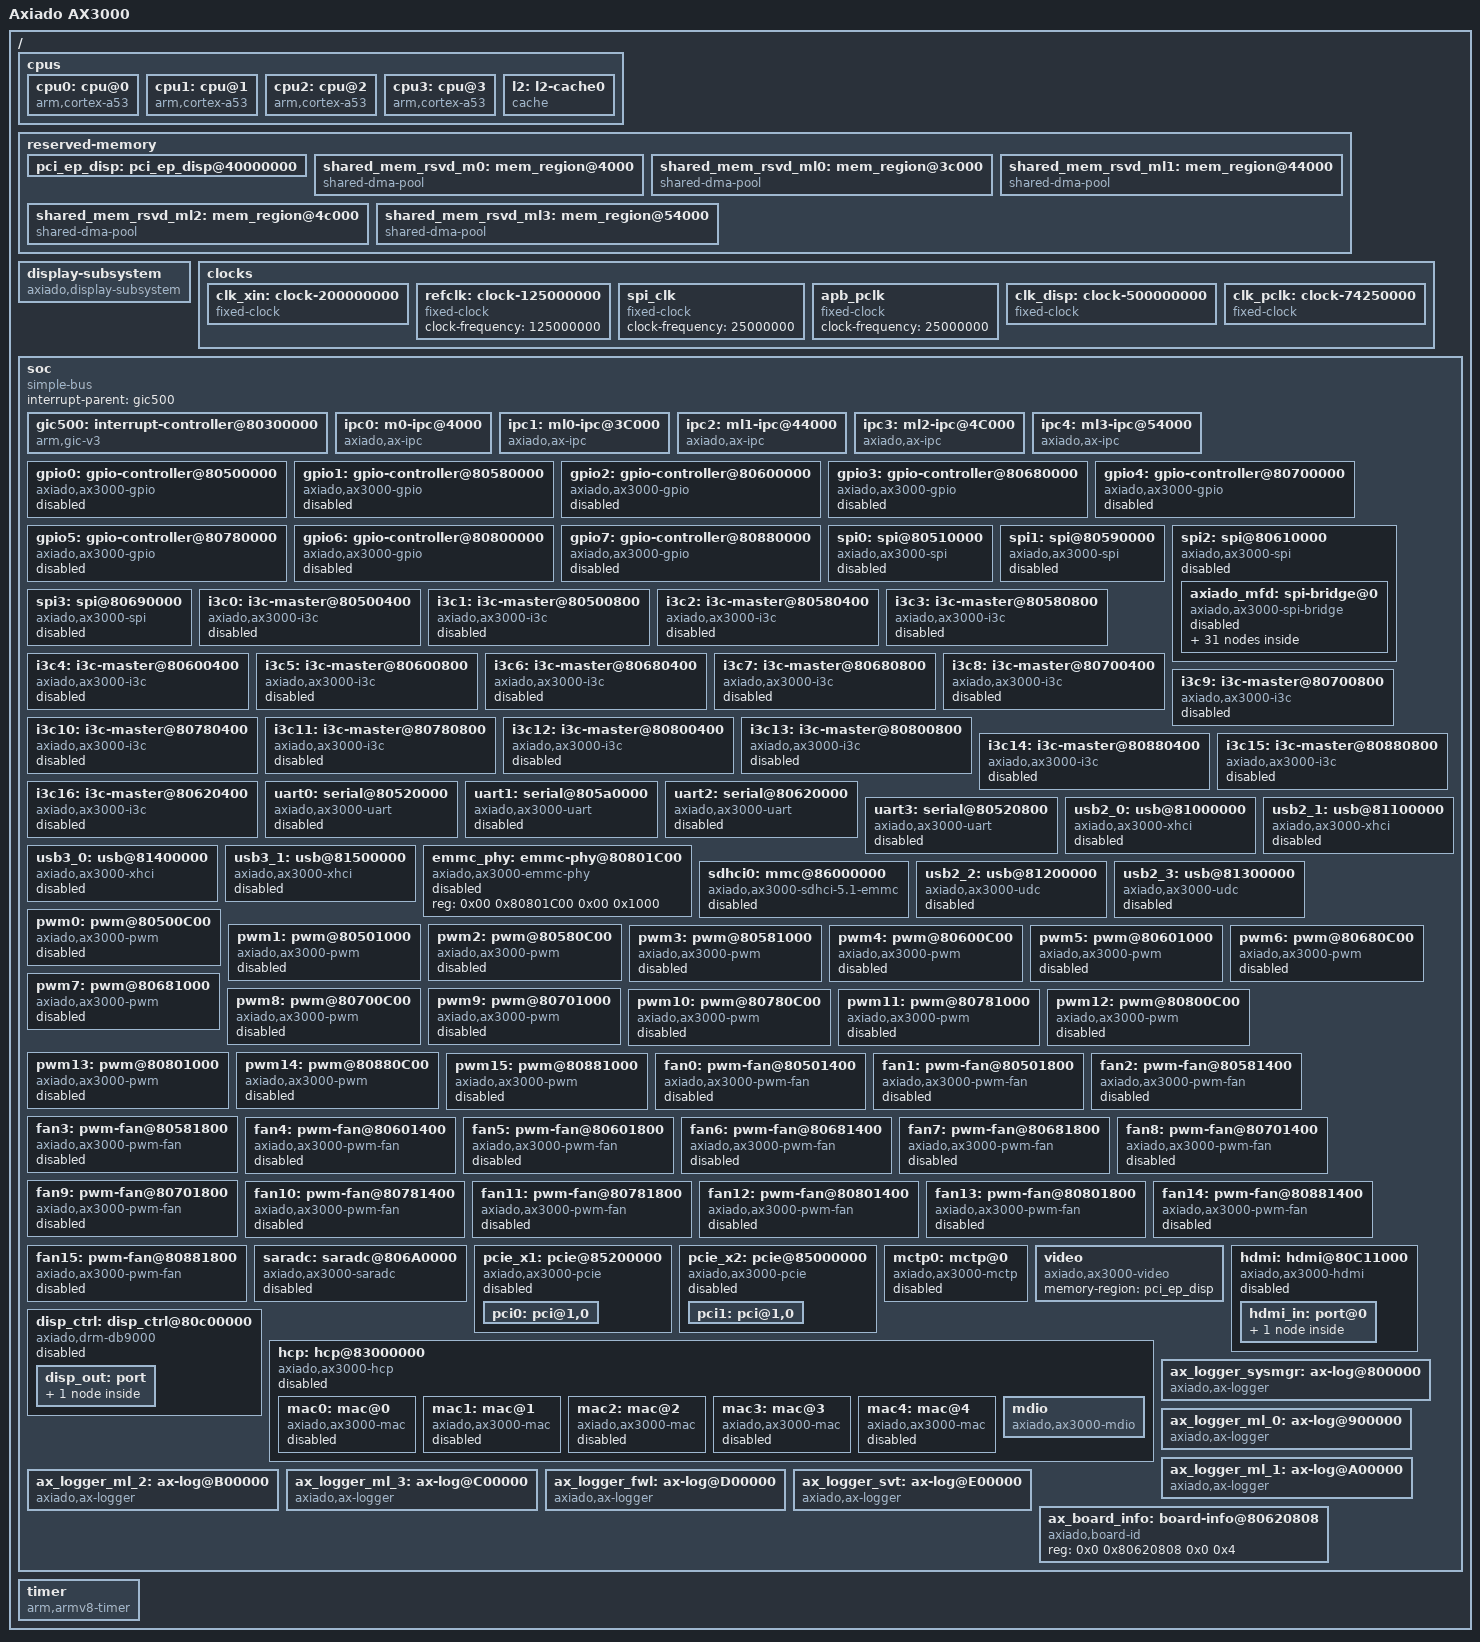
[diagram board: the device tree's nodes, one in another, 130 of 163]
// SPDX-License-Identifier: GPL-2.0+
/*
 * Copyright (c) 2021-25 Axiado Corporation (or its affiliates).
 */

/dts-v1/;

#include <dt-bindings/interrupt-controller/irq.h>
#include <dt-bindings/interrupt-controller/arm-gic.h>

/memreserve/ 0x3c0013a0 0x00000008;	/* cpu-release-addr */
/ {
	model = "Axiado AX3000";
	interrupt-parent = <&gic500>;
	#address-cells = <2>;
	#size-cells = <2>;

	cpus {
		#address-cells = <2>;
		#size-cells = <0>;

		cpu0: cpu@0 {
			device_type = "cpu";
			compatible = "arm,cortex-a53";
			reg = <0x0 0x0>;
			enable-method = "spin-table";
			cpu-release-addr = <0x0 0x3c0013a0>;
			d-cache-size = <0x8000>;
			d-cache-line-size = <64>;
			d-cache-sets = <128>;
			i-cache-size = <0x8000>;
			i-cache-line-size = <64>;
			i-cache-sets = <256>;
			next-level-cache = <&l2>;
		};

		cpu1: cpu@1 {
			device_type = "cpu";
			compatible = "arm,cortex-a53";
			reg = <0x0 0x1>;
			enable-method = "spin-table";
			cpu-release-addr = <0x0 0x3c0013a0>;
			d-cache-size = <0x8000>;
			d-cache-line-size = <64>;
			d-cache-sets = <128>;
			i-cache-size = <0x8000>;
			i-cache-line-size = <64>;
			i-cache-sets = <256>;
			next-level-cache = <&l2>;
		};

		cpu2: cpu@2 {
			device_type = "cpu";
			compatible = "arm,cortex-a53";
			reg = <0x0 0x2>;
			enable-method = "spin-table";
			cpu-release-addr = <0x0 0x3c0013a0>;
			d-cache-size = <0x8000>;
			d-cache-line-size = <64>;
			d-cache-sets = <128>;
			i-cache-size = <0x8000>;
			i-cache-line-size = <64>;
			i-cache-sets = <256>;
			next-level-cache = <&l2>;
		};

		cpu3: cpu@3 {
			device_type = "cpu";
			compatible = "arm,cortex-a53";
			reg = <0x0 0x3>;
			enable-method = "spin-table";
			cpu-release-addr = <0x0 0x3c0013a0>;
			d-cache-size = <0x8000>;
			d-cache-line-size = <64>;
			d-cache-sets = <128>;
			i-cache-size = <0x8000>;
			i-cache-line-size = <64>;
			i-cache-sets = <256>;
			next-level-cache = <&l2>;
		};

		l2: l2-cache0 {
			compatible = "cache";
			cache-size = <0x100000>;
			cache-unified;
			cache-line-size = <64>;
			cache-sets = <1024>;
			cache-level = <2>;
		};
	};

	reserved-memory {
		#address-cells = <2>;
		#size-cells = <2>;
		ranges;
		pci_ep_disp: pci_ep_disp@40000000 {
			reg = <0x00 0x40000000 0x00 0x8000000>,
			      <0x00 0x48000000 0x00 0x100000>;
			no-map;
		};
		shared_mem_rsvd_m0: mem_region@4000 {
			compatible = "shared-dma-pool";
			reg = <0x00 0x4000 0x00 0x8000>;
			no-map;
		};
		shared_mem_rsvd_ml0: mem_region@3c000 {
			compatible = "shared-dma-pool";
			reg = <0x00 0x3c000 0x00 0x8000>;
			no-map;
		};
		shared_mem_rsvd_ml1: mem_region@44000 {
			compatible = "shared-dma-pool";
			reg = <0x00 0x44000 0x00 0x8000>;
			no-map;
		};
		shared_mem_rsvd_ml2: mem_region@4c000 {
			compatible = "shared-dma-pool";
			reg = <0x00 0x4c000 0x00 0x8000>;
			no-map;
		};
		shared_mem_rsvd_ml3: mem_region@54000 {
			compatible = "shared-dma-pool";
			reg = <0x00 0x54000 0x00 0x8000>;
			no-map;
		};
	};

	display-subsystem {
		compatible = "axiado,display-subsystem";
	};

	clocks {
		clk_xin: clock-200000000 {
			compatible = "fixed-clock";
			#clock-cells = <0>;
			clock-frequency = <200000000>;
			clock-output-names = "clk_xin";
		};

		refclk: clock-125000000 {
			compatible = "fixed-clock";
			#clock-cells = <0>;
			clock-frequency = <125000000>;
		};

		spi_clk: spi_clk {
			compatible = "fixed-clock";
			#clock-cells = <0>;
			clock-frequency = <25000000>;
		};

		apb_pclk: apb_pclk {
			compatible = "fixed-clock";
			#clock-cells = <0>;
			clock-frequency = <25000000>;
		};

		clk_disp: clock-500000000 {
			compatible = "fixed-clock";
			#clock-cells = <0>;
			clock-frequency = <500000000>; /* 500MHz Clock half of CPU clock*/
			clock-output-names = "clk_disp";
		};

		clk_pclk: clock-74250000 {
			compatible = "fixed-clock";
			#clock-cells = <0>;
			clock-frequency = <74250000>;
			clock-output-names = "clk_pclk";
		};
	};

	soc {
		compatible = "simple-bus";
		ranges;
		#address-cells = <2>;
		#size-cells = <2>;
		interrupt-parent = <&gic500>;

		gic500: interrupt-controller@80300000 {
			compatible = "arm,gic-v3";
			reg = <0x00 0x80300000 0x00 0x10000>,
			      <0x00 0x80380000 0x00 0x80000>;
			ranges;
			#interrupt-cells = <3>;
			#address-cells = <2>;
			#size-cells = <2>;
			interrupt-controller;
			#redistributor-regions = <1>;
			interrupts = <GIC_PPI 9 IRQ_TYPE_LEVEL_HIGH>;
		};
		ipc0: m0-ipc@4000 {
			compatible = "axiado,ax-ipc";
			#interrupt-cells = <1>;
			reg = <0x00 0x4000 0x00 0x8000>,    /* Shared mem info */
			<0x0 0x88014120 0x0 0x4>,       /* TX intr mem info */
			<0x0 0x88014154 0x0 0x4>,       /* RX intr mem info */
			<0x0 0x02A00000 0x0 0x100000>,  /* Data buffers for A53->M0*/
			<0x0 0x80620804 0x0 0x4>,       /* scratchpad1 register, for boot status */
			<0x0 0x01500000 0x0 0x4>;       /* scratchpad region, for mmc partition */
			memory-region = <&shared_mem_rsvd_m0>;
			interrupts = <GIC_SPI 171 IRQ_TYPE_LEVEL_HIGH>;
			LABEL = "M0";
			interrupt-parent = <&gic500>;
			status = "okay";
		};
		ipc1: ml0-ipc@3C000 {
			compatible = "axiado,ax-ipc";
			#interrupt-cells = <1>;
			reg = <0x00 0x3C000 0x00 0x8000>,   /* Shared mem info */
			<0x0 0x88014140 0x0 0x4>,       /* TX intr mem info */
			<0x0 0x88000070 0x0 0x4>,       /* RX intr mem info */
			<0x0 0x04800000 0x0 0x100000>;  /* Data buffers for A53->ML0 */
			memory-region = <&shared_mem_rsvd_ml0>;
			interrupts = <GIC_SPI 195 IRQ_TYPE_LEVEL_HIGH>;
			LABEL = "ML0";
			interrupt-parent = <&gic500>;
			status = "okay";
		};
		ipc2: ml1-ipc@44000 {
			compatible = "axiado,ax-ipc";
			#interrupt-cells = <1>;
			reg = <0x00 0x44000 0x00 0x8000>,   /* Shared mem info */
			<0x0 0x88014144 0x0 0x4>,       /* TX intr mem info */
			<0x0 0x88002070 0x0 0x4>,       /* RX intr mem info */
			<0x0 0x11000000 0x0 0x100000>;  /* Data buffers for A53->ML1*/
			memory-region = <&shared_mem_rsvd_ml1>;
			interrupts = <GIC_SPI 196 IRQ_TYPE_LEVEL_HIGH>;
			LABEL = "ML1";
			interrupt-parent = <&gic500>;
			status = "okay";
		};
		ipc3: ml2-ipc@4C000 {
			compatible = "axiado,ax-ipc";
			#interrupt-cells = <1>;
			reg = <0x00 0x4C000 0x00 0x8000>,   /* Shared mem info */
			<0x0 0x88014148 0x0 0x4>,       /* TX intr mem info */
			<0x0 0x88004070 0x0 0x4>,       /* RX intr mem info */
			<0x0 0x1D800000 0x0 0x100000>;  /* Data buffers for A53->ML2*/
			memory-region = <&shared_mem_rsvd_ml2>;
			interrupts = <GIC_SPI 197 IRQ_TYPE_LEVEL_HIGH>;
			LABEL = "ML2";
			interrupt-parent = <&gic500>;
			status = "okay";
		};
		ipc4: ml3-ipc@54000 {
			compatible = "axiado,ax-ipc";
			#interrupt-cells = <1>;
			reg = <0x00 0x54000 0x00 0x8000>,   /* Shared mem info */
			<0x0 0x8801414c 0x0 0x4>,       /* TX intr mem info */
			<0x0 0x88006070 0x0 0x4>,       /* RX intr mem info */
			<0x0 0x2A000000 0x0 0x100000>;  /* Data buffers for A53->ML3*/
			memory-region = <&shared_mem_rsvd_ml3>;
			interrupts = <GIC_SPI 198 IRQ_TYPE_LEVEL_HIGH>;
			LABEL = "ML3";
			interrupt-parent = <&gic500>;
			status = "okay";
		};
		/* GPIO Controller banks 0 - 7 */
		gpio0: gpio-controller@80500000 {
			compatible = "axiado,ax3000-gpio", "cdns,gpio-r1p02";
			reg = <0x00 0x80500000 0x00 0x400>;
			clocks = <&refclk>;
			interrupt-parent = <&gic500>;
			interrupts = <GIC_SPI 183 IRQ_TYPE_LEVEL_HIGH>;
			gpio-controller;
			#gpio-cells = <2>;
			interrupt-controller;
			#interrupt-cells = <2>;
			status = "disabled";
		};

		gpio1: gpio-controller@80580000 {
			compatible = "axiado,ax3000-gpio", "cdns,gpio-r1p02";
			reg = <0x00 0x80580000 0x00 0x400>;
			clocks = <&refclk>;
			interrupt-parent = <&gic500>;
			interrupts = <GIC_SPI 184 IRQ_TYPE_LEVEL_HIGH>;
			gpio-controller;
			#gpio-cells = <2>;
			interrupt-controller;
			#interrupt-cells = <2>;
			status = "disabled";
		};

		gpio2: gpio-controller@80600000 {
			compatible = "axiado,ax3000-gpio", "cdns,gpio-r1p02";
			reg = <0x00 0x80600000 0x00 0x400>;
			clocks = <&refclk>;
			interrupt-parent = <&gic500>;
			interrupts = <GIC_SPI 185 IRQ_TYPE_LEVEL_HIGH>;
			gpio-controller;
			#gpio-cells = <2>;
			interrupt-controller;
			#interrupt-cells = <2>;
			status = "disabled";
		};

		gpio3: gpio-controller@80680000 {
			compatible = "axiado,ax3000-gpio", "cdns,gpio-r1p02";
			reg = <0x00 0x80680000 0x00 0x400>;
			clocks = <&refclk>;
			interrupt-parent = <&gic500>;
			interrupts = <GIC_SPI 186 IRQ_TYPE_LEVEL_HIGH>;
			gpio-controller;
			#gpio-cells = <2>;
			interrupt-controller;
			#interrupt-cells = <2>;
			status = "disabled";
		};

		gpio4: gpio-controller@80700000 {
			compatible = "axiado,ax3000-gpio", "cdns,gpio-r1p02";
			reg = <0x00 0x80700000 0x00 0x400>;
			clocks = <&refclk>;
			interrupt-parent = <&gic500>;
			interrupts = <GIC_SPI 187 IRQ_TYPE_LEVEL_HIGH>;
			gpio-controller;
			#gpio-cells = <2>;
			interrupt-controller;
			#interrupt-cells = <2>;
			status = "disabled";
		};

		gpio5: gpio-controller@80780000 {
			compatible = "axiado,ax3000-gpio", "cdns,gpio-r1p02";
			reg = <0x00 0x80780000 0x00 0x400>;
			clocks = <&refclk>;
			interrupt-parent = <&gic500>;
			interrupts = <GIC_SPI 188 IRQ_TYPE_LEVEL_HIGH>;
			gpio-controller;
			#gpio-cells = <2>;
			interrupt-controller;
			#interrupt-cells = <2>;
			status = "disabled";
		};

		gpio6: gpio-controller@80800000 {
			compatible = "axiado,ax3000-gpio", "cdns,gpio-r1p02";
			reg = <0x00 0x80800000 0x00 0x400>;
			clocks = <&refclk>;
			interrupt-parent = <&gic500>;
			interrupts = <GIC_SPI 189 IRQ_TYPE_LEVEL_HIGH>;
			gpio-controller;
			#gpio-cells = <2>;
			interrupt-controller;
			#interrupt-cells = <2>;
			status = "disabled";
		};

		gpio7: gpio-controller@80880000 {
			compatible = "axiado,ax3000-gpio", "cdns,gpio-r1p02";
			reg = <0x00 0x80880000 0x00 0x400>;
			clocks = <&refclk>;
			interrupt-parent = <&gic500>;
			interrupts = <GIC_SPI 190 IRQ_TYPE_LEVEL_HIGH>;
			gpio-controller;
			#gpio-cells = <2>;
			interrupt-controller;
			#interrupt-cells = <2>;
			status = "disabled";
		};

		spi0: spi@80510000 {
			compatible = "axiado,ax3000-spi";
			reg = <0x00 0x80510000 0x00 0x1000>;
			clock-names = "ref", "pclk";
			clocks = <&spi_clk>, <&apb_pclk>;
			interrupt-parent = <&gic500>;
			interrupts = <GIC_SPI 115 IRQ_TYPE_LEVEL_HIGH>;
			num-cs = <1>;
			status = "disabled";
		};

		spi1: spi@80590000 {
			compatible = "axiado,ax3000-spi";
			reg = <0x00 0x80590000 0x00 0x1000>;
			clock-names = "ref", "pclk";
			clocks = <&spi_clk>, <&apb_pclk>;
			interrupt-parent = <&gic500>;
			interrupts = <GIC_SPI 116 IRQ_TYPE_LEVEL_HIGH>;
			num-cs = <1>;
			status = "disabled";
		};

		spi2: spi@80610000 {
			compatible = "axiado,ax3000-spi";
			reg = <0x00 0x80610000 0x00 0x1000>;
			clock-names = "ref", "pclk";
			clocks = <&spi_clk>, <&apb_pclk>;
			interrupt-parent = <&gic500>;
			interrupts = <GIC_SPI 117 IRQ_TYPE_LEVEL_HIGH>;
			num-cs = <1>;
			#address-cells = <1>;
			#size-cells = <0>;
			status = "disabled";

			/* MFD parent device representing the Solang peripheral */
			axiado_mfd: spi-bridge@0 {
				compatible = "axiado,ax3000-spi-bridge", "axiado,spi-bridge";
				/* Current spi-axiado drv ignores the value from the device tree */
				spi-max-frequency = <25000000>;
				reg = <0x0>; /* Chip select 0 */
				#address-cells = <1>;
				#size-cells = <1>;
				interrupt-controller;
				#interrupt-cells = <1>;
				interrupt-names = "mfd-shared";
				interrupt-parent = <&gpio6>;
				/* GPIO_212 LTPI-I2C Interrupt */
				interrupts = <20 IRQ_TYPE_LEVEL_HIGH>;
				status = "disabled";
				mfd_i2c0: i2c-ssif@0 {
					compatible = "axiado,xps-iic-slave";
					#address-cells = <1>;
					#size-cells = <0>;
					reg = <0x0 0x800>;
					clocks = <&refclk &clk_xin>;
					#interrupt-cells = <2>;
					interrupt-parent = <&gpio6>;
					interrupts = <11 IRQ_TYPE_LEVEL_HIGH>; /* GPIO_203 I2C slave interrupt */
					clock-frequency = <100000>;
					/* Axiado-specific IRQ thread tuning */
					axiado,irq-rt-priority = <90>; /* 1..99, SCHED_FIFO */
					axiado,irq-cpu = <2>; /* pin threaded IRQ to CPU2 */
					status = "disabled";
					ssif-bmc@10 {
						compatible = "ssif-bmc";
						reg = <0x10>;
						status = "disabled";
					};
				};
				mfd_i2c0_cdns: i2c@0 {
					compatible = "axiado,ax3000-i2c";
					#address-cells = <1>;
					#size-cells = <0>;
					reg = <0x0 0x800>;
					clocks = <&refclk &clk_xin>;
					#interrupt-cells = <2>;
					interrupt-parent = <&gpio6>;
					/* GPIO_203 I2C slave interrupt */
					interrupts = <11 IRQ_TYPE_LEVEL_HIGH>;
					clock-frequency = <100000>;
					status = "disabled";
				};
				/* Child node for the second Cadence I2C IP */
				mfd_i2c1: i2c@800 {
					compatible = "axiado,ax3000-i2c";
					reg = <0x0800 0x400>; /* i2c_1_base_addr and size */
					#interrupt-cells = <2>;
					interrupt-parent = <&gpio6>;
					/* Direct GPIO 204 IRQ */
					interrupts = <12 IRQ_TYPE_LEVEL_HIGH>;
					clocks = <&refclk &clk_xin>;
					clock-frequency = <100000>;
					status = "disabled";
				};
				mfd_i2c2: i2c@c00 {
					compatible = "axiado,ax3000-i2c";
					reg = <0x0c00 0x400>; /* i2c_2_base_addr and size */
					#interrupt-cells = <2>;
					interrupt-parent = <&gpio6>;
					/* Direct GPIO 205 IRQ */
					interrupts = <13 IRQ_TYPE_LEVEL_HIGH>;
					clocks = <&refclk &clk_xin>;
					clock-frequency = <100000>;
					status = "disabled";
				};
				mfd_i2c3: i2c@1000 {
					compatible = "axiado,ax3000-i2c";
					reg = <0x1000 0x400>; /* i2c_3_base_addr and size */
					#interrupt-cells = <2>;
					interrupt-parent = <&gpio6>;
					/* Direct GPIO 206 IRQ */
					interrupts = <14 IRQ_TYPE_LEVEL_HIGH>;
					clocks = <&refclk &clk_xin>;
					clock-frequency = <100000>;
					status = "disabled";
				};
				mfd_i2c4: i2c@1400 {
					compatible = "axiado,ax3000-i2c";
					reg = <0x1400 0x400>; /* i2c_4_base_addr and size */
					#interrupt-cells = <2>;
					interrupt-parent = <&gpio6>;
					/* Direct GPIO 207 IRQ */
					interrupts = <15 IRQ_TYPE_LEVEL_HIGH>;
					clocks = <&refclk &clk_xin>;
					clock-frequency = <100000>;
					status = "disabled";
				};
				mfd_i2c5: i2c@1800 {
					compatible = "axiado,ax3000-i2c";
					reg = <0x1800 0x400>; /* i2c_5_base_addr and size */
					#interrupt-cells = <2>;
					interrupt-parent = <&gpio6>;
					/* Direct GPIO 208 IRQ */
					interrupts = <16 IRQ_TYPE_LEVEL_HIGH>;
					clocks = <&refclk &clk_xin>;
					clock-frequency = <100000>;
					status = "disabled";
				};
				mfd_i2c6: i2c@1c00 {
					compatible = "axiado,ax3000-i2c";
					reg = <0x1c00 0x400>; /* i2c_6_base_addr and size */
					#interrupt-cells = <2>;
					interrupt-parent = <&gpio6>;
					/* Direct GPIO 217 IRQ */
					interrupts = <25 IRQ_TYPE_LEVEL_HIGH>;
					clocks = <&refclk &clk_xin>;
					clock-frequency = <100000>;
					status = "disabled";
				};
				mfd_i2c7: i2c@2000 {
					compatible = "axiado,ax3000-i2c";
					reg = <0x2000 0x400>; /* i2c_7_base_addr and size */
					#interrupt-cells = <2>;
					interrupt-parent = <&gpio6>;
					/* Direct GPIO 219 IRQ */
					interrupts = <27 IRQ_TYPE_LEVEL_HIGH>;
					clocks = <&refclk &clk_xin>;
					clock-frequency = <100000>;
					status = "disabled";
				};
				mfd_i2c8: i2c@2400 {
					compatible = "axiado,ax3000-i2c";
					reg = <0x2400 0x400>; /* i2c_8_base_addr and size */
					#interrupt-cells = <2>;
					interrupt-parent = <&gpio6>;
					/* Direct GPIO 220 IRQ */
					interrupts = <28 IRQ_TYPE_LEVEL_HIGH>;
					clocks = <&refclk &clk_xin>;
					clock-frequency = <100000>;
					status = "disabled";
				};
				mfd_i2c9: i2c@2800 {
					compatible = "axiado,ax3000-i2c";
					reg = <0x2800 0x400>; /* i2c_9_base_addr and size */
					#interrupt-cells = <2>;
					interrupt-parent = <&gpio6>;
					/* Direct GPIO 221 IRQ */
					interrupts = <29 IRQ_TYPE_LEVEL_HIGH>;
					clocks = <&refclk &clk_xin>;
					clock-frequency = <100000>;
					status = "disabled";
				};
				mfd_i2c10: i2c@2c00 {
					compatible = "axiado,ax3000-i2c";
					reg = <0x2c00 0x400>; /* i2c_10_base_addr and size */
					#interrupt-cells = <2>;
					interrupt-parent = <&gpio6>;
					/* Direct GPIO 222 IRQ */
					interrupts = <30 IRQ_TYPE_LEVEL_HIGH>;
					clocks = <&refclk &clk_xin>;
					clock-frequency = <100000>;
					status = "disabled";
				};
				mfd_i2c11: i2c@3000 {
					compatible = "axiado,ax3000-i2c";
					reg = <0x3000 0x400>; /* i2c_11_base_addr and size */
					#interrupt-cells = <2>;
					interrupt-parent = <&gpio7>;
					/* Direct GPIO 245 IRQ */
					interrupts = <21 IRQ_TYPE_LEVEL_HIGH>;
					clocks = <&refclk &clk_xin>;
					clock-frequency = <100000>;
					status = "disabled";
				};
				mfd_i2c12: i2c@3400 {
					compatible = "axiado,ax3000-i2c";
					reg = <0x3400 0x400>; /* i2c_12_base_addr and size */
					#interrupt-cells = <2>;
					interrupt-parent = <&gpio7>;
					/* Direct GPIO 237 IRQ */
					interrupts = <13 IRQ_TYPE_LEVEL_HIGH>;
					clocks = <&refclk &clk_xin>;
					clock-frequency = <100000>;
					status = "disabled";
				};
				mfd_i2c13: i2c@3800 {
					compatible = "axiado,ax3000-i2c";
					reg = <0x3800 0x400>; /* i2c_13_base_addr and size */
					#interrupt-cells = <2>;
					interrupt-parent = <&gpio7>;
					/* Direct GPIO 238 IRQ */
					interrupts = <14 IRQ_TYPE_LEVEL_HIGH>;
					clocks = <&refclk &clk_xin>;
					clock-frequency = <100000>;
					status = "disabled";
				};
				mfd_i2c14: i2c@3c00 {
					compatible = "axiado,ax3000-i2c";
					reg = <0x3c00 0x400>; /* i2c_14_base_addr and size */
					#interrupt-cells = <2>;
					interrupt-parent = <&gpio7>;
					/* Direct GPIO 239 IRQ */
					interrupts = <15 IRQ_TYPE_LEVEL_HIGH>;
					clocks = <&refclk &clk_xin>;
					clock-frequency = <100000>;
					status = "disabled";
				};
				mfd_i2c15: i2c@4000 {
					compatible = "axiado,ax3000-i2c";
					reg = <0x4000 0x400>; /* i2c_15_base_addr and size */
					#interrupt-cells = <2>;
					interrupt-parent = <&gpio7>;
					/* Direct GPIO 240 IRQ */
					interrupts = <16 IRQ_TYPE_LEVEL_HIGH>;
					clocks = <&refclk &clk_xin>;
					clock-frequency = <100000>;
					status = "disabled";
				};
				mfd_i2c16: i2c@4400 {
					compatible = "axiado,ax3000-i2c";
					reg = <0x4400 0x400>; /* i2c_16_base_addr and size */
					#interrupt-cells = <2>;
					interrupt-parent = <&gpio7>;
					/* Direct GPIO 241 IRQ */
					interrupts = <17 IRQ_TYPE_LEVEL_HIGH>;
					clocks = <&refclk &clk_xin>;
					clock-frequency = <100000>;
					status = "disabled";
				};
				ltpi_i2c17: i2c@4800 {
					compatible = "axiado,ax3000-i2c";
					reg = <0x4800 0x400>; /* i2c_14_base_addr and size */
					interrupt-parent = <&axiado_mfd>;
					#interrupt-cells = <1>;
					interrupts = <17>;
					clocks = <&refclk &clk_xin>;
					clock-frequency = <100000>;
					status = "disabled";
				};
				ltpi_i2c18: i2c@4c00 {
					compatible = "axiado,ax3000-i2c";
					reg = <0x4c00 0x400>; /* i2c_18_base_addr and size */
					interrupt-controller;
					#interrupt-cells = <1>;
					interrupts = <18>;
					clocks = <&refclk &clk_xin>;
					clock-frequency = <100000>;
					status = "disabled";
				};
				ltpi_i2c19: i2c@5000 {
					compatible = "axiado,ax3000-i2c";
					reg = <0x5000 0x400>; /* i2c_19_base_addr and size */
					interrupt-controller;
					#interrupt-cells = <1>;
					interrupts = <19>;
					clocks = <&refclk &clk_xin>;
					clock-frequency = <100000>;
					status = "disabled";
				};
				ltpi_i2c20: i2c@5400 {
					compatible = "axiado,ax3000-i2c";
					reg = <0x5400 0x400>; /* i2c_20 and size */
					interrupt-controller;
					#interrupt-cells = <1>;
					interrupts = <20>;
					clocks = <&refclk &clk_xin>;
					clock-frequency = <100000>;
					status = "disabled";
				};
				ltpi_i2c21: i2c@5800 {
					compatible = "axiado,ax3000-i2c";
					reg = <0x5800 0x400>; /* i2c_21 and size */
					interrupt-controller;
					#interrupt-cells = <1>;
					interrupts = <21>;
					clocks = <&refclk &clk_xin>;
					clock-frequency = <100000>;
					status = "disabled";
				};
				ltpi_i2c22: i2c@5c00 {
					compatible = "axiado,ax3000-i2c";
					reg = <0x5c00 0x400>; /* i2c_22 and size */
					interrupt-controller;
					#interrupt-cells = <1>;
					interrupts = <22>;
					clocks = <&refclk &clk_xin>;
					clock-frequency = <100000>;
					status = "disabled";
				};
				mfd_sgpio0: sgpio@a000 {
					compatible = "axiado,sgpio";
					reg = <0xa000 0x800>;
					gpio-controller;
					#gpio-cells = <2>;
					interrupt-parent = <&gpio6>;
					/* GPIO_209 SGPIO Interrupt */
					interrupts = <17 IRQ_TYPE_LEVEL_HIGH>;
					/* Design variants 128 bit or 512 bit */
					design-variant = <128>;
					/* Supports maximum of 128 pins */
					ngpios = <128>;
					/* SGPIO Clock frequency 12 MHz */
					bus-frequency = <12000000>;
					apb-frequency = <100000000>;
					dout-init = <0x00000000 0x00000000 0x00000000 0x00000000>;
					status = "disabled";
				};
				mfd_ltpi0: ltpi@8000 {
					compatible = "axiado,ltpi";
					/* Base offset for regmap */
					reg = <0x8000 0x2000>;
					gpio-controller;
					#gpio-cells = <2>;
					interrupt-parent = <&gpio6>;
					/* GPIO_210 SGPIO Interrupt */
					interrupts = <18 IRQ_TYPE_LEVEL_HIGH>;
					interrupt-controller;
					#interrupt-cells = <2>;
					/* Supports maximum of 128 pins */
					ngpios = <128>;
					dout-init = <0x00000000 0x00000000 0x00000000 0x00000000>;
					status = "disabled";
				};
				mfd_espi: espi@c000 {
					compatible = "axiado,ax3000-espi-regmap";
					reg = <0xc000 0x1000>,
						<0xd000 0x1000>,
						<0xe000 0x1000>;
					reg-names = "espi-core", "espi-perif", "espi-atu";
					interrupt-parent = <&gpio6>;
					interrupts = <19 IRQ_TYPE_LEVEL_HIGH>,   /* GPIO_211 eSPI core */
						   <23 IRQ_TYPE_LEVEL_HIGH>;   /* GPIO_215 external logic */
					interrupt-names = "espi-core-intr", "ext-logic-intr";
					interrupt-controller;
					#interrupt-cells = <1>;
					#address-cells = <1>;
					#size-cells = <1>;
					status = "disabled";

					espi_kcs0: espi-kcs@0 {
						compatible = "axiado,ax3000-kcs-bmc";
						reg = <0x0 0x10>;
						interrupts = <0>; /* Virtual IRQ: bit 0 in external logic ISR */
						interrupt-parent = <&mfd_espi>;
						channel-index = <0>;
						io-addr = <0xCA2>; /* IPMI 2.0: 0xCA2(data) + 0xCA3 (status) */
						host-status-offset = <0x1>; /* 1-byte offset per IPMI 2.0 spec */
						status = "disabled";
					};

					espi_snoop: espi-snoop@C0 {
						compatible = "axiado,ax3000-espi-snoop";
						reg = <0xC0 0x10>;
						interrupts = <13>;
						interrupt-parent = <&mfd_espi>;
						io-addr = <0x80>;
						status = "disabled";
					};

					espi_uart0: espi-uart@40 {
						compatible = "axiado,ax3000-espi-uart";
						reg = <0x40 0x02>;
						interrupts = <5>; /* Virtual IRQ: bit 5 */
						interrupt-parent = <&mfd_espi>;
						clock-names = "uart_clk", "pclk";
						clocks = <&refclk &refclk>;
						channel-index = <0>;
						io-addr = <0x3F8>;
						fifo-size = <16>;
						cpu-fifo-size = <64>;
						status = "disabled";
					};
				};
			};
		};

		spi3: spi@80690000 {
			compatible = "axiado,ax3000-spi";
			reg = <0x00 0x80690000 0x00 0x1000>;
			clock-names = "ref", "pclk";
			clocks = <&spi_clk>, <&apb_pclk>;
			interrupt-parent = <&gic500>;
			interrupts = <GIC_SPI 118 IRQ_TYPE_LEVEL_HIGH>;
			num-cs = <1>;
			status = "disabled";
		};

		/* I3C Controller 0 - 16 */
		i3c0: i3c-master@80500400 {
			compatible = "axiado,ax3000-i3c", "cdns,i3c-master";
			reg = <0x00 0x80500400 0x00 0x400>;
			clocks = <&refclk &clk_xin>;
			clock-names = "pclk", "sysclk";
			interrupt-parent = <&gic500>;
			interrupts = <GIC_SPI 76 IRQ_TYPE_LEVEL_HIGH>;
			i2c-scl-hz = <100000>;
			i3c-scl-hz = <400000>;
			#address-cells = <3>;
			#size-cells = <0>;
			status = "disabled";
			disable-ibir;
			use-i2c-alias;
		};

		i3c1: i3c-master@80500800 {
			compatible = "axiado,ax3000-i3c", "cdns,i3c-master";
			reg = <0x00 0x80500800 0x00 0x400>;
			clocks = <&refclk &clk_xin>;
			clock-names = "pclk", "sysclk";
			interrupt-parent = <&gic500>;
			interrupts = <GIC_SPI 77 IRQ_TYPE_LEVEL_HIGH>;
			i2c-scl-hz = <100000>;
			i3c-scl-hz = <400000>;
			#address-cells = <3>;
			#size-cells = <0>;
			status = "disabled";
			disable-ibir;
			use-i2c-alias;
		};

		i3c2: i3c-master@80580400 {
			compatible = "axiado,ax3000-i3c", "cdns,i3c-master";
			reg = <0x00 0x80580400 0x00 0x400>;
			clocks = <&refclk &clk_xin>;
			clock-names = "pclk", "sysclk";
			interrupt-parent = <&gic500>;
			interrupts = <GIC_SPI 78 IRQ_TYPE_LEVEL_HIGH>;
			i2c-scl-hz = <100000>;
			i3c-scl-hz = <400000>;
			#address-cells = <3>;
			#size-cells = <0>;
			status = "disabled";
			disable-ibir;
			use-i2c-alias;
		};

		i3c3: i3c-master@80580800 {
			compatible = "axiado,ax3000-i3c", "cdns,i3c-master";
			reg = <0x00 0x80580800 0x00 0x400>;
			clocks = <&refclk &clk_xin>;
			clock-names = "pclk", "sysclk";
			interrupt-parent = <&gic500>;
			interrupts = <GIC_SPI 79 IRQ_TYPE_LEVEL_HIGH>;
			i2c-scl-hz = <100000>;
			i3c-scl-hz = <400000>;
			#address-cells = <3>;
			#size-cells = <0>;
			status = "disabled";
			disable-ibir;
			use-i2c-alias;
		};

		i3c4: i3c-master@80600400 {
			compatible = "axiado,ax3000-i3c", "cdns,i3c-master";
			reg = <0x00 0x80600400 0x00 0x400>;
			clocks = <&refclk &clk_xin>;
			clock-names = "pclk", "sysclk";
			interrupt-parent = <&gic500>;
			interrupts = <GIC_SPI 80 IRQ_TYPE_LEVEL_HIGH>;
			i2c-scl-hz = <100000>;
			i3c-scl-hz = <400000>;
			#address-cells = <3>;
			#size-cells = <0>;
			status = "disabled";
			disable-ibir;
			use-i2c-alias;
		};

		i3c5: i3c-master@80600800 {
			compatible = "axiado,ax3000-i3c", "cdns,i3c-master";
			reg = <0x00 0x80600800 0x00 0x400>;
			clocks = <&refclk &clk_xin>;
			clock-names = "pclk", "sysclk";
			interrupt-parent = <&gic500>;
			interrupts = <GIC_SPI 81 IRQ_TYPE_LEVEL_HIGH>;
			i2c-scl-hz = <100000>;
			i3c-scl-hz = <400000>;
			#address-cells = <3>;
			#size-cells = <0>;
			status = "disabled";
			disable-ibir;
			use-i2c-alias;
		};

		i3c6: i3c-master@80680400 {
			compatible = "axiado,ax3000-i3c", "cdns,i3c-master";
			reg = <0x00 0x80680400 0x00 0x400>;
			clocks = <&refclk &clk_xin>;
			clock-names = "pclk", "sysclk";
			interrupt-parent = <&gic500>;
			interrupts = <GIC_SPI 82 IRQ_TYPE_LEVEL_HIGH>;
			i2c-scl-hz = <100000>;
			i3c-scl-hz = <400000>;
			#address-cells = <3>;
			#size-cells = <0>;
			status = "disabled";
			disable-ibir;
			use-i2c-alias;
		};

		i3c7: i3c-master@80680800 {
			compatible = "axiado,ax3000-i3c", "cdns,i3c-master";
			reg = <0x00 0x80680800 0x00 0x400>;
			clocks = <&refclk &clk_xin>;
			clock-names = "pclk", "sysclk";
			interrupt-parent = <&gic500>;
			interrupts = <GIC_SPI 83 IRQ_TYPE_LEVEL_HIGH>;
			i2c-scl-hz = <100000>;
			i3c-scl-hz = <400000>;
			#address-cells = <3>;
			#size-cells = <0>;
			status = "disabled";
			disable-ibir;
			use-i2c-alias;
		};

		i3c8: i3c-master@80700400 {
			compatible = "axiado,ax3000-i3c", "cdns,i3c-master";
			reg = <0x00 0x80700400 0x00 0x400>;
			clocks = <&refclk &clk_xin>;
			clock-names = "pclk", "sysclk";
			interrupt-parent = <&gic500>;
			interrupts = <GIC_SPI 84 IRQ_TYPE_LEVEL_HIGH>;
			i2c-scl-hz = <100000>;
			i3c-scl-hz = <400000>;
			#address-cells = <3>;
			#size-cells = <0>;
			status = "disabled";
			disable-ibir;
			use-i2c-alias;
		};

		i3c9: i3c-master@80700800 {
			compatible = "axiado,ax3000-i3c", "cdns,i3c-master";
			reg = <0x00 0x80700800 0x00 0x400>;
			clocks = <&refclk &clk_xin>;
			clock-names = "pclk", "sysclk";
			interrupt-parent = <&gic500>;
			interrupts = <GIC_SPI 85 IRQ_TYPE_LEVEL_HIGH>;
			i2c-scl-hz = <100000>;
			i3c-scl-hz = <400000>;
			#address-cells = <3>;
			#size-cells = <0>;
			status = "disabled";
			disable-ibir;
			use-i2c-alias;
		};

		i3c10: i3c-master@80780400 {
			compatible = "axiado,ax3000-i3c", "cdns,i3c-master";
			reg = <0x00 0x80780400 0x00 0x400>;
			clocks = <&refclk &clk_xin>;
			clock-names = "pclk", "sysclk";
			interrupt-parent = <&gic500>;
			interrupts = <GIC_SPI 86 IRQ_TYPE_LEVEL_HIGH>;
			i2c-scl-hz = <100000>;
			i3c-scl-hz = <400000>;
			#address-cells = <3>;
			#size-cells = <0>;
			status = "disabled";
			disable-ibir;
			use-i2c-alias;
		};

		i3c11: i3c-master@80780800 {
			compatible = "axiado,ax3000-i3c", "cdns,i3c-master";
			reg = <0x00 0x80780800 0x00 0x400>;
			clocks = <&refclk &clk_xin>;
			clock-names = "pclk", "sysclk";
			interrupt-parent = <&gic500>;
			interrupts = <GIC_SPI 87 IRQ_TYPE_LEVEL_HIGH>;
			i2c-scl-hz = <100000>;
			i3c-scl-hz = <400000>;
			#address-cells = <3>;
			#size-cells = <0>;
			status = "disabled";
			disable-ibir;
			use-i2c-alias;
		};

		i3c12: i3c-master@80800400 {
			compatible = "axiado,ax3000-i3c", "cdns,i3c-master";
			reg = <0x00 0x80800400 0x00 0x400>;
			clocks = <&refclk &clk_xin>;
			clock-names = "pclk", "sysclk";
			interrupt-parent = <&gic500>;
			interrupts = <GIC_SPI 88 IRQ_TYPE_LEVEL_HIGH>;
			i2c-scl-hz = <100000>;
			i3c-scl-hz = <400000>;
			#address-cells = <3>;
			#size-cells = <0>;
			status = "disabled";
			disable-ibir;
			use-i2c-alias;
		};

		i3c13: i3c-master@80800800 {
			compatible = "axiado,ax3000-i3c", "cdns,i3c-master";
			reg = <0x00 0x80800800 0x00 0x400>;
			clocks = <&refclk &clk_xin>;
			clock-names = "pclk", "sysclk";
			interrupt-parent = <&gic500>;
			interrupts = <GIC_SPI 89 IRQ_TYPE_LEVEL_HIGH>;
			i2c-scl-hz = <100000>;
			i3c-scl-hz = <400000>;
			#address-cells = <3>;
			#size-cells = <0>;
			status = "disabled";
			disable-ibir;
			use-i2c-alias;
		};

		i3c14: i3c-master@80880400 {
			compatible = "axiado,ax3000-i3c", "cdns,i3c-master";
			reg = <0x00 0x80880400 0x00 0x400>;
			clocks = <&refclk &clk_xin>;
			clock-names = "pclk", "sysclk";
			interrupt-parent = <&gic500>;
			interrupts = <GIC_SPI 90 IRQ_TYPE_LEVEL_HIGH>;
			i2c-scl-hz = <100000>;
			i3c-scl-hz = <400000>;
			#address-cells = <3>;
			#size-cells = <0>;
			status = "disabled";
			disable-ibir;
			use-i2c-alias;
		};

		i3c15: i3c-master@80880800 {
			compatible = "axiado,ax3000-i3c", "cdns,i3c-master";
			reg = <0x00 0x80880800 0x00 0x400>;
			clocks = <&refclk &clk_xin>;
			clock-names = "pclk", "sysclk";
			interrupt-parent = <&gic500>;
			interrupts = <GIC_SPI 91 IRQ_TYPE_LEVEL_HIGH>;
			i2c-scl-hz = <100000>;
			i3c-scl-hz = <400000>;
			#address-cells = <3>;
			#size-cells = <0>;
			status = "disabled";
			disable-ibir;
			use-i2c-alias;
		};

		i3c16: i3c-master@80620400 {
			compatible = "axiado,ax3000-i3c", "cdns,i3c-master";
			reg = <0x00 0x80620400 0x00 0x400>;
			clocks = <&refclk &clk_xin>;
			clock-names = "pclk", "sysclk";
			interrupt-parent = <&gic500>;
			interrupts = <GIC_SPI 92 IRQ_TYPE_LEVEL_HIGH>;
			i2c-scl-hz = <100000>;
			i3c-scl-hz = <400000>;
			#address-cells = <3>;
			#size-cells = <0>;
			status = "disabled";
			disable-ibir;
			use-i2c-alias;
		};

		uart0: serial@80520000 {
			compatible = "axiado,ax3000-uart", "cdns,uart-r1p12";
			reg = <0x00 0x80520000 0x00 0x100>;
			interrupt-parent = <&gic500>;
			interrupts = <GIC_SPI 112 IRQ_TYPE_LEVEL_HIGH>;
			clock-names = "uart_clk", "pclk";
			clocks = <&refclk &refclk>;
			status = "disabled";
		};

		uart1: serial@805a0000 {
			compatible = "axiado,ax3000-uart", "cdns,uart-r1p12";
			reg = <0x00 0x805A0000 0x00 0x100>;
			interrupt-parent = <&gic500>;
			interrupts = <GIC_SPI 113 IRQ_TYPE_LEVEL_HIGH>;
			clock-names = "uart_clk", "pclk";
			clocks = <&refclk &refclk>;
			status = "disabled";
		};

		uart2: serial@80620000 {
			compatible = "axiado,ax3000-uart", "cdns,uart-r1p12";
			reg = <0x00 0x80620000 0x00 0x100>;
			interrupt-parent = <&gic500>;
			interrupts = <GIC_SPI 114 IRQ_TYPE_LEVEL_HIGH>;
			clock-names = "uart_clk", "pclk";
			clocks = <&refclk &refclk>;
			status = "disabled";
		};

		uart3: serial@80520800 {
			compatible = "axiado,ax3000-uart", "cdns,uart-r1p12";
			reg = <0x00 0x80520800 0x00 0x100>;
			interrupt-parent = <&gic500>;
			interrupts = <GIC_SPI 170 IRQ_TYPE_LEVEL_HIGH>;
			clock-names = "uart_clk", "pclk";
			clocks = <&refclk &refclk>;
			status = "disabled";
		};

		usb2_0: usb@81000000 {
			compatible = "axiado,ax3000-xhci", "generic-xhci";
			reg = <0x00 0x81000000 0x00 0x100000>;
			interrupt-parent = <&gic500>;
			interrupts = <GIC_SPI 19 IRQ_TYPE_LEVEL_HIGH>;
			status = "disabled";
		};

		usb2_1: usb@81100000 {
			compatible = "axiado,ax3000-xhci", "generic-xhci";
			reg = <0x00 0x81100000 0x00 0x100000>;
			interrupt-parent = <&gic500>;
			interrupts = <GIC_SPI 20 IRQ_TYPE_LEVEL_HIGH>;
			status = "disabled";
		};

		usb3_0: usb@81400000 {
			compatible = "axiado,ax3000-xhci", "generic-xhci";
			reg = <0x00 0x81400000 0x00 0x100000>;
			interrupt-parent = <&gic500>;
			interrupts = <GIC_SPI 17 IRQ_TYPE_LEVEL_HIGH>;
			status = "disabled";
		};

		usb3_1: usb@81500000 {
			compatible = "axiado,ax3000-xhci", "generic-xhci";
			reg = <0x00 0x81500000 0x00 0x100000>;
			interrupt-parent = <&gic500>;
			interrupts = <GIC_SPI 18 IRQ_TYPE_LEVEL_HIGH>;
			status = "disabled";
		};

		emmc_phy: emmc-phy@80801C00 {
			compatible = "axiado,ax3000-emmc-phy";
			reg = <0x00 0x80801C00 0x00 0x1000>;
			#phy-cells = <0>;
			status = "disabled";
		};

		sdhci0: mmc@86000000 {
			compatible = "axiado,ax3000-sdhci-5.1-emmc", "arasan,sdhci-5.1";
			reg = <0x0 0x86000000 0x00 0x1000>;
			clock-names = "clk_xin", "clk_ahb";
			clocks = <&clk_xin &clk_xin>;
			interrupt-parent = <&gic500>;
			interrupts = <0 123 4>;
			bus-width = <8>;
			phys = <&emmc_phy>;
			phy-names = "phy_arasan";
			status = "disabled";
		};

		usb2_2: usb@81200000 {
			compatible = "axiado,ax3000-udc";
			reg = <0x00 0x81200000 0x00 0x100000>;
			reg-names = "mmio";
			interrupt-parent = <&gic500>;
			interrupts = <GIC_SPI 21 IRQ_TYPE_LEVEL_HIGH>;
			status = "disabled";
		};

		usb2_3: usb@81300000 {
			compatible = "axiado,ax3000-udc";
			reg = <0x00 0x81300000 0x00 0x100000>;
			reg-names = "mmio";
			interrupt-parent = <&gic500>;
			interrupts = <GIC_SPI 22 IRQ_TYPE_LEVEL_HIGH>;
			status = "disabled";
		};

		pwm0: pwm@80500C00 {
			compatible = "axiado,ax3000-pwm";
			reg = <0x00 0x80500C00 0x00 0x400>;
			#pwm-cells = <2>;
			clocks = <&refclk &refclk>;
			interrupt-parent = <&gic500>;
			interrupts = <GIC_SPI 93 IRQ_TYPE_LEVEL_HIGH>;
			status = "disabled";
		};

		pwm1: pwm@80501000 {
			compatible = "axiado,ax3000-pwm";
			reg = <0x00 0x80501000 0x00 0x400>;
			#pwm-cells = <2>;
			clocks = <&refclk &refclk>;
			interrupt-parent = <&gic500>;
			interrupts = <GIC_SPI 94 IRQ_TYPE_LEVEL_HIGH>;
			status = "disabled";
		};

		pwm2: pwm@80580C00 {
			compatible = "axiado,ax3000-pwm";
			reg = <0x00 0x80580C00 0x00 0x400>;
			#pwm-cells = <2>;
			clocks = <&refclk &refclk>;
			interrupt-parent = <&gic500>;
			interrupts = <GIC_SPI 95 IRQ_TYPE_LEVEL_HIGH>;
			status = "disabled";
		};

		pwm3: pwm@80581000 {
			compatible = "axiado,ax3000-pwm";
			#pwm-cells = <2>;
			clocks = <&refclk &refclk>;
			interrupt-parent = <&gic500>;
			interrupts = <GIC_SPI 96 IRQ_TYPE_LEVEL_HIGH>;
			reg = <0x00 0x80581000 0x00 0x400>;
			status = "disabled";
		};

		pwm4: pwm@80600C00 {
			compatible = "axiado,ax3000-pwm";
			#pwm-cells = <2>;
			clocks = <&refclk &refclk>;
			interrupt-parent = <&gic500>;
			interrupts = <GIC_SPI 97 IRQ_TYPE_LEVEL_HIGH>;
			reg = <0x00 0x80600C00 0x00 0x400>;
			status = "disabled";
		};

		pwm5: pwm@80601000 {
			compatible = "axiado,ax3000-pwm";
			#pwm-cells = <2>;
			clocks = <&refclk &refclk>;
			interrupt-parent = <&gic500>;
			interrupts = <GIC_SPI 98 IRQ_TYPE_LEVEL_HIGH>;
			reg = <0x00 0x80601000 0x00 0x400>;
			status = "disabled";
		};

		pwm6: pwm@80680C00 {
			compatible = "axiado,ax3000-pwm";
			#pwm-cells = <2>;
			clocks = <&refclk &refclk>;
			interrupt-parent = <&gic500>;
			interrupts = <GIC_SPI 99 IRQ_TYPE_LEVEL_HIGH>;
			reg = <0x00 0x80680C00 0x00 0x400>;
			status = "disabled";
		};

		pwm7: pwm@80681000 {
			compatible = "axiado,ax3000-pwm";
			#pwm-cells = <2>;
			clocks = <&refclk &refclk>;
			interrupt-parent = <&gic500>;
			interrupts = <GIC_SPI 100 IRQ_TYPE_LEVEL_HIGH>;
			reg = <0x00 0x80681000 0x00 0x400>;
			status = "disabled";
		};

		pwm8: pwm@80700C00 {
			compatible = "axiado,ax3000-pwm";
			#pwm-cells = <2>;
			clocks = <&refclk &refclk>;
			interrupt-parent = <&gic500>;
			interrupts = <GIC_SPI 101 IRQ_TYPE_LEVEL_HIGH>;
			reg = <0x00 0x80700C00 0x00 0x400>;
			status = "disabled";
		};

		pwm9: pwm@80701000 {
			compatible = "axiado,ax3000-pwm";
			#pwm-cells = <2>;
			clocks = <&refclk &refclk>;
			interrupt-parent = <&gic500>;
			interrupts = <GIC_SPI 102 IRQ_TYPE_LEVEL_HIGH>;
			reg = <0x00 0x80701000 0x00 0x400>;
			status = "disabled";
		};

		pwm10: pwm@80780C00 {
			compatible = "axiado,ax3000-pwm";
			#pwm-cells = <2>;
			clocks = <&refclk &refclk>;
			interrupt-parent = <&gic500>;
			interrupts = <GIC_SPI 103 IRQ_TYPE_LEVEL_HIGH>;
			reg = <0x00 0x80780C00 0x00  0x400>;
			status = "disabled";
		};

		pwm11: pwm@80781000 {
			compatible = "axiado,ax3000-pwm";
			#pwm-cells = <2>;
			clocks = <&refclk &refclk>;
			interrupt-parent = <&gic500>;
			interrupts = <GIC_SPI 104 IRQ_TYPE_LEVEL_HIGH>;
			reg = <0x00 0x80781000 0x00 0x400>;
			status = "disabled";
		};

		pwm12: pwm@80800C00 {
			compatible = "axiado,ax3000-pwm";
			#pwm-cells = <2>;
			clocks = <&refclk &refclk>;
			interrupt-parent = <&gic500>;
			interrupts = <GIC_SPI 105 IRQ_TYPE_LEVEL_HIGH>;
			reg = <0x00 0x80800C00 0x00 0x400>;
			status = "disabled";
		};

		pwm13: pwm@80801000 {
			compatible = "axiado,ax3000-pwm";
			#pwm-cells = <2>;
			clocks = <&refclk &refclk>;
			interrupt-parent = <&gic500>;
			interrupts = <GIC_SPI 106 IRQ_TYPE_LEVEL_HIGH>;
			reg = <0x00 0x80801000 0x00 0x400>;
			status = "disabled";
		};

		pwm14: pwm@80880C00 {
			compatible = "axiado,ax3000-pwm";
			#pwm-cells = <2>;
			clocks = <&refclk &refclk>;
			interrupt-parent = <&gic500>;
			interrupts = <GIC_SPI 107 IRQ_TYPE_LEVEL_HIGH>;
			reg = <0x00 0x80880C00 0x00  0x400>;
			status = "disabled";
		};

		pwm15: pwm@80881000 {
			compatible = "axiado,ax3000-pwm";
			#pwm-cells = <2>;
			clocks = <&refclk &refclk>;
			interrupt-parent = <&gic500>;
			interrupts = <GIC_SPI 108 IRQ_TYPE_LEVEL_HIGH>;
			reg = <0x00 0x80881000 0x00 0x400>;
			status = "disabled";
		};

		fan0: pwm-fan@80501400 {
			compatible = "axiado,ax3000-pwm-fan";
			interrupt-parent = <&gic500>;
			interrupts = <GIC_SPI 150 IRQ_TYPE_LEVEL_HIGH>;
			reg = <0x00 0x80501400 0x00 0x400>;
			pwms = <&pwm0 0 400>;
			status = "disabled";
		};

		fan1: pwm-fan@80501800 {
			compatible = "axiado,ax3000-pwm-fan";
			interrupt-parent = <&gic500>;
			interrupts = <GIC_SPI 151 IRQ_TYPE_LEVEL_HIGH>;
			reg = <0x00 0x80501800 0x00 0x400>;
			pwms = <&pwm1 0 400>;
			status = "disabled";
		};

		fan2: pwm-fan@80581400 {
			compatible = "axiado,ax3000-pwm-fan";
			interrupt-parent = <&gic500>;
			interrupts = <GIC_SPI 152 IRQ_TYPE_LEVEL_HIGH>;
			reg = <0x00 0x80581400 0x00 0x400>;
			pwms = <&pwm2 0 400>;
			status = "disabled";
		};

		fan3: pwm-fan@80581800 {
			compatible = "axiado,ax3000-pwm-fan";
			interrupt-parent = <&gic500>;
			interrupts = <GIC_SPI 153 IRQ_TYPE_LEVEL_HIGH>;
			reg = <0x00 0x80581800 0x00 0x400>;
			pwms = <&pwm3 0 400>;
			status = "disabled";
		};

		fan4: pwm-fan@80601400 {
			compatible = "axiado,ax3000-pwm-fan";
			interrupt-parent = <&gic500>;
			interrupts = <GIC_SPI 154 IRQ_TYPE_LEVEL_HIGH>;
			reg = <0x00 0x80601400 0x00 0x400>;
			pwms = <&pwm4 0 400>;
			status = "disabled";
		};

		fan5: pwm-fan@80601800 {
			compatible = "axiado,ax3000-pwm-fan";
			interrupt-parent = <&gic500>;
			interrupts = <GIC_SPI 155 IRQ_TYPE_LEVEL_HIGH>;
			reg = <0x00 0x80601800 0x00 0x400>;
			pwms = <&pwm5 0 400>;
			status = "disabled";
		};

		fan6: pwm-fan@80681400 {
			compatible = "axiado,ax3000-pwm-fan";
			interrupt-parent = <&gic500>;
			interrupts = <GIC_SPI 156 IRQ_TYPE_LEVEL_HIGH>;
			reg = <0x00 0x80681400 0x00 0x400>;
			pwms = <&pwm6 0 400>;
			status = "disabled";
		};

		fan7: pwm-fan@80681800 {
			compatible = "axiado,ax3000-pwm-fan";
			interrupt-parent = <&gic500>;
			interrupts = <GIC_SPI 157 IRQ_TYPE_LEVEL_HIGH>;
			reg = <0x00 0x80681800 0x00 0x400>;
			pwms = <&pwm7 0 400>;
			status = "disabled";
		};

		fan8: pwm-fan@80701400 {
			compatible = "axiado,ax3000-pwm-fan";
			interrupt-parent = <&gic500>;
			interrupts = <GIC_SPI 158 IRQ_TYPE_LEVEL_HIGH>;
			reg = <0x00 0x80701400 0x00 0x400>;
			pwms = <&pwm8 0 400>;
			status = "disabled";
		};

		fan9: pwm-fan@80701800 {
			compatible = "axiado,ax3000-pwm-fan";
			interrupt-parent = <&gic500>;
			interrupts = <GIC_SPI 159 IRQ_TYPE_LEVEL_HIGH>;
			reg = <0x00 0x80701800 0x00 0x400>;
			pwms = <&pwm9 0 400>;
			status = "disabled";
		};

		fan10: pwm-fan@80781400 {
			compatible = "axiado,ax3000-pwm-fan";
			interrupt-parent = <&gic500>;
			interrupts = <GIC_SPI 160 IRQ_TYPE_LEVEL_HIGH>;
			reg = <0x00 0x80781400 0x00 0x400>;
			pwms = <&pwm10 0 400>;
			status = "disabled";
		};

		fan11: pwm-fan@80781800 {
			compatible = "axiado,ax3000-pwm-fan";
			interrupt-parent = <&gic500>;
			interrupts = <GIC_SPI 161 IRQ_TYPE_LEVEL_HIGH>;
			reg = <0x00 0x80781800 0x00 0x400>;
			pwms = <&pwm11 0 400>;
			status = "disabled";
		};

		fan12: pwm-fan@80801400 {
			compatible = "axiado,ax3000-pwm-fan";
			interrupt-parent = <&gic500>;
			interrupts = <GIC_SPI 162 IRQ_TYPE_LEVEL_HIGH>;
			reg = <0x00 0x80801400 0x00 0x400>;
			pwms = <&pwm12 0 400>;
			status = "disabled";
		};

		fan13: pwm-fan@80801800 {
			compatible = "axiado,ax3000-pwm-fan";
			interrupt-parent = <&gic500>;
			interrupts = <GIC_SPI 163 IRQ_TYPE_LEVEL_HIGH>;
			reg = <0x00 0x80801800 0x00 0x400>;
			pwms = <&pwm13 0 400>;
			status = "disabled";
		};

		fan14: pwm-fan@80881400 {
			compatible = "axiado,ax3000-pwm-fan";
			interrupt-parent = <&gic500>;
			interrupts = <GIC_SPI 164 IRQ_TYPE_LEVEL_HIGH>;
			reg = <0x00 0x80881400 0x00 0x400>;
			pwms = <&pwm14 0 400>;
			status = "disabled";
		};

		fan15: pwm-fan@80881800 {
			compatible = "axiado,ax3000-pwm-fan";
			interrupt-parent = <&gic500>;
			interrupts = <GIC_SPI 165 IRQ_TYPE_LEVEL_HIGH>;
			reg = <0x00 0x80881800 0x00 0x400>;
			pwms = <&pwm15 0 400>;
			status = "disabled";
		};

		saradc: saradc@806A0000 {
			compatible = "axiado,ax3000-saradc";
			reg = <0x00 0x806A0000 0x00 0x400>;
			interrupt-parent = <&gic500>;
			interrupts = <GIC_SPI 166 IRQ_TYPE_LEVEL_HIGH>;
			clocks = <&refclk>;
			clock-names = "refclk";
			#io-channel-cells = <1>;
			status = "disabled";
		};

		pcie_x1: pcie@85200000 {
			compatible = "axiado,ax3000-pcie";
			status = "disabled";
			device_type = "pci";
			device_role = "vga"; /* VGA EP */
			reg = <0 0x85200000 0 0x1000>, /* CSR reg */
			      <0 0x85300000 0 0x4000>, /* PHY reg */
			      <0 0x85202000 0 0x1000>, /* CFG space */
			      <0 0x85280000 0 0x80000>, /* MBX reg */
			      <0 0x80702400 0 0x100>, /* IOCTL reg */
			      <0 0x85240000 0 0x1000>; /* EXT reg */
			reg-names = "csr", "phy", "cfg", "mbx", "ioctl", "ext";
			#address-cells = <3>;
			#size-cells = <2>;
			interrupts = <GIC_SPI 33 IRQ_TYPE_LEVEL_HIGH>; /* MSI interrupt */
			interrupt-names = "msi";
			interrupt-map-mask = <0 0 0 7>;
			interrupt-map = <0 0 0 1 &gic500 0>, /* int_a */
					<0 0 0 2 &gic500 1>, /* int_b */
					<0 0 0 3 &gic500 2>, /* int_c */
					<0 0 0 4 &gic500 3>; /* int_d */
			num-lanes = <1>;
			clocks = <&clk_pclk> ;
			clock-names = "clk_pclk";
			bus-range = <0x00 0xff>;
			ranges = <0x83000000 0x3 0xE0000000 0x3 0xE0000000 0x0 0x400000>,
				 /* 4M - Port0 Config */
				 <0x82000000 0x0 0x90000000 0x0 0x90000000 0x0 0x8000000>,
				 /* 128M - prefetchable */
				 <0xc2000000 0x0 0x98000000 0x0 0x98000000 0x0 0x100000>;
				 /* 1M - non-prefetchable */

			pci0: pci@1,0 {
				device_type = "pci";
				assigned-addresses = <0x83000800 0x3 0xE0000000 0 0x400000>;
				reg = <0x00800 0 0 0 0>;
				#address-cells = <3>;
				#size-cells = <2>;
				ranges;
			};
		};

		pcie_x2: pcie@85000000 {
			compatible = "axiado,ax3000-pcie";
			status = "disabled";
			device_type = "pci";
			device_role = "host"; /* Host Bridge */
			reg = <0 0x85000000 0 0x1000>, /* CSR reg */
			      <0 0x85100000 0 0x4000>, /* PHY reg */
			      <0 0x85002000 0 0x4000>, /* CFG space */
			      <0 0x85080000 0 0x80000>, /* MBX reg */
			      <0 0x80702400 0 0x100>, /* IOCTL reg */
			      <0 0x85040000 0 0x1000>; /* EXT reg */
			reg-names = "csr", "phy", "cfg", "mbx", "ioctl","ext";
			num-lanes = <2>;
			#address-cells = <3>;
			#size-cells = <2>;
			interrupts = <GIC_SPI 61 IRQ_TYPE_LEVEL_HIGH>; /* MSI interrupt */
			interrupt-names = "msi";
			interrupt-map-mask = <0 0 0 7>;
			interrupt-map = <0 0 0 1 &gic500 0>,
					<0 0 0 2 &gic500 1>,
					<0 0 0 3 &gic500 2>,
					<0 0 0 4 &gic500 3>;
			clocks = <&clk_pclk> ;
			clock-names = "clk_pclk";
			bus-range = <0x00 0xff>;
			ranges = <0x83000000 0x2 0xE0000000 0x2 0xE0000000 0x0 0x400000>,
				 <0xc2000000 0x0 0x99000000 0x0 0x99000000 0x0 0x100000>,
				 <0x82000000 0x0 0xa0000000 0x0 0xa0000000 0x0 0x10000000>;

			pci1: pci@1,0 {
				device_type = "pci";
				assigned-addresses = <0x83000800 0x2 0xE0000000 0 0x400000>;
				reg = <0x00800 0 0 0 0>;
				#address-cells = <3>;
				#size-cells = <2>;
				ranges;
			};
		};

		mctp0: mctp@0 {
			compatible = "axiado,ax3000-mctp";
			reg = <0x0 0x802E0000 0x00 0x20000>;
			reg-names = "ocm-base";
			/* For determining A0, B0 ... etc
			 * Encodes whether this is EP or RC as well.
			 * For EPs, bit 8 is set to 0x1.
			 */
			axrc-version = <0x001>;
			/* for axrc-version == 1, this indicates
			 * Which RC to bind to for VDM generation
			 * <2> -> X2, <1> -> X1
			 */
			axrc-vdm-id = <2>;
			pcie-phandle = <&pcie_x2>;
			isolated-cpu = <3>;
			status = "disabled";
		};

		video: video {
			compatible = "axiado,ax3000-video";
			memory-region = <&pci_ep_disp>;
		};

		disp_ctrl: disp_ctrl@80c00000 {
			compatible = "axiado,drm-db9000";
			reg = <0x0 0x80C00000 0x0 0x1000>;
			memory-region = <&pci_ep_disp>;
			interrupts = <GIC_SPI 14 IRQ_TYPE_LEVEL_HIGH>;
			clocks = <&clk_disp &clk_pclk> ;
			clock-names = "clk_disp", "clk_pclk";
			bits-per-pixel = <32>;
			bus-width = <24>;
			paddr-disp = <0x40000000>;
			status = "disabled";

			disp_out: port {
				#address-cells = <1>;
				#size-cells = <0>;

				disp_out_hdmi: endpoint@0 {
					reg = <0>;
					remote-endpoint = <&hdmi_in_disp>;
				};
			};
		};

		hdmi: hdmi@80C11000 {
			compatible = "axiado,ax3000-hdmi";
			reg = <0x00 0x80C11000 0x00 0x4000>;
			memory-region = <&pci_ep_disp>;
			interrupts = <GIC_SPI 16 IRQ_TYPE_LEVEL_HIGH>;
			clocks =  <&clk_disp>, <&clk_pclk>;
			clock-names = "clk_disp", "clk_pclk";
			#address-cells = <1>;
			#size-cells = <0>;
			status = "disabled";

			hdmi_in: port@0 {
				#address-cells = <1>;
				#size-cells = <0>;

				hdmi_in_disp: endpoint@0 {
					reg = <0>;
					remote-endpoint = <&disp_out_hdmi>;
				};
			};
		};

		/* HCP (Header and Crypto Processing Engine) */
		hcp: hcp@83000000 {
			compatible = "axiado,ax3000-hcp";
			#address-cells = <1>;
			#size-cells = <0>;
			/*
			 * All memory regions for the HCP subsystem:
			 * - EIP-197 crypto engine
			 * - SHIM registers
			 * - PHY CSR
			 */
			reg = <0x0 0x83000000 0x0 0x100000>,  /* EIP-197 (1MB) */
			      <0x0 0x83100000 0x0 0x4000>,    /* SHIM regs (16KB) */
			      <0x0 0x87000000 0x0 0x50000>;   /* PHY CSR (320KB) */
			reg-names = "eip197", "shim", "phy-csr";
			/*
			 * All interrupts for HCP:
			 * IRQ 0: EIP-197 crypto
			 * IRQ 1-4: Rings 0-3
			 * IRQ 5-9: MACs 0-4
			 */
			interrupt-parent = <&gic500>;
			interrupts = <GIC_SPI 0 IRQ_TYPE_LEVEL_HIGH>,  /* EIP-197 */
			             <GIC_SPI 1 IRQ_TYPE_LEVEL_HIGH>,   /* Ring 0 */
			             <GIC_SPI 2 IRQ_TYPE_LEVEL_HIGH>,   /* Ring 1 */
			             <GIC_SPI 3 IRQ_TYPE_LEVEL_HIGH>,   /* Ring 2 */
			             <GIC_SPI 4 IRQ_TYPE_LEVEL_HIGH>,   /* Ring 3 */
			             <GIC_SPI 5 IRQ_TYPE_LEVEL_HIGH>,   /* MAC 0 */
			             <GIC_SPI 6 IRQ_TYPE_LEVEL_HIGH>,   /* MAC 1 */
			             <GIC_SPI 7 IRQ_TYPE_LEVEL_HIGH>,   /* MAC 2 */
			             <GIC_SPI 8 IRQ_TYPE_LEVEL_HIGH>,   /* MAC 3 */
			             <GIC_SPI 9 IRQ_TYPE_LEVEL_HIGH>;   /* MAC 4 */
			interrupt-names = "eip197", "ring0", "ring1", "ring2", "ring3",
			                  "mac0", "mac1", "mac2", "mac3", "mac4";
			status = "disabled";

			/* MAC 0: 10G RXAUI */
			mac0: mac@0 {
				compatible = "axiado,ax3000-mac";
				reg = <0>;
				phy-mode = "rxaui";
				status = "disabled";
			};

			/* MAC 1: 1G SGMII */
			mac1: mac@1 {
				compatible = "axiado,ax3000-mac";
				reg = <1>;
				phy-mode = "sgmii";
				status = "disabled";
			};

			/* MAC 2: 1G SGMII */
			mac2: mac@2 {
				compatible = "axiado,ax3000-mac";
				reg = <2>;
				phy-mode = "sgmii";
				status = "disabled";
			};

			/* MAC 3: 1G SGMII */
			mac3: mac@3 {
				compatible = "axiado,ax3000-mac";
				reg = <3>;
				phy-mode = "sgmii";
				status = "disabled";
			};

			/* MAC 4: 1G SGMII */
			mac4: mac@4 {
				compatible = "axiado,ax3000-mac";
				reg = <4>;
				phy-mode = "sgmii";
				status = "disabled";
			};

			/* MDIO bus for PHY management */
			mdio: mdio {
				compatible = "axiado,ax3000-mdio";
				#address-cells = <1>;
				#size-cells = <0>;
			};
		};

		ax_logger_sysmgr: ax-log@800000 {
			compatible = "axiado,ax-logger";
			reg = <0x00 0x800000 0x00 0xfa00>;
			node-name = "log-sysmgr";
		};

		ax_logger_ml_0: ax-log@900000 {
			compatible = "axiado,ax-logger";
			reg = <0x00 0x900000 0x00 0xfa00>;
			node-name = "log-ml-0";
		};

		ax_logger_ml_1: ax-log@A00000 {
			compatible = "axiado,ax-logger";
			reg = <0x00 0xA00000 0x00 0xfa00>;
			node-name = "log-ml-1";
		};

		ax_logger_ml_2: ax-log@B00000 {
			compatible = "axiado,ax-logger";
			reg = <0x00 0xB00000 0x00 0xfa00>;
			node-name = "log-ml-2";
		};

		ax_logger_ml_3: ax-log@C00000 {
			compatible = "axiado,ax-logger";
			reg = <0x00 0xC00000 0x00 0xfa00>;
			node-name = "log-ml-3";
		};

		ax_logger_fwl: ax-log@D00000 {
			compatible = "axiado,ax-logger";
			reg = <0x00 0xD00000 0x00 0xfa00>;
			node-name = "log-fwl";
		};

		ax_logger_svt: ax-log@E00000 {
			compatible = "axiado,ax-logger";
			reg = <0x00 0xE00000 0x00 0xfa00>;
			node-name = "log-svt";
		};

		ax_board_info: board-info@80620808 {
			compatible = "axiado,board-id";
			reg = <0x0 0x80620808 0x0 0x4>;
			status = "okay";
		};

	};

	timer {
		compatible = "arm,armv8-timer";
		interrupt-parent = <&gic500>;
		interrupts = <GIC_PPI 13 IRQ_TYPE_LEVEL_HIGH>,
			   <GIC_PPI 14 IRQ_TYPE_LEVEL_HIGH>,
			   <GIC_PPI 11 IRQ_TYPE_LEVEL_HIGH>,
			   <GIC_PPI 10 IRQ_TYPE_LEVEL_HIGH>;
	};
};
